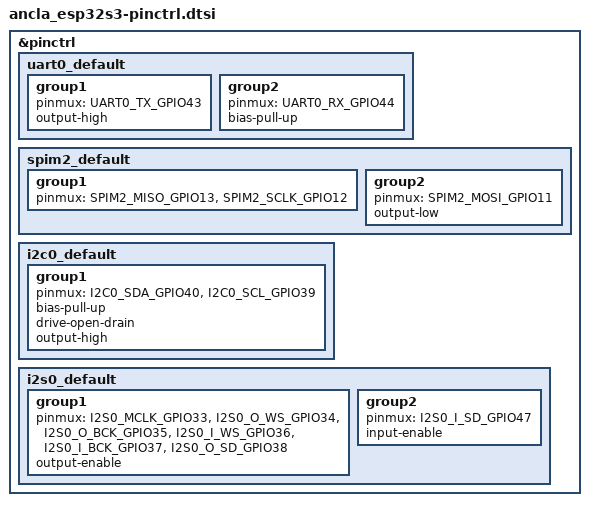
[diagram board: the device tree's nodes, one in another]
/*
 * Copyright (c) 2026 Innovaforce
 *
 * SPDX-License-Identifier: Apache-2.0
 */

#include <zephyr/dt-bindings/pinctrl/esp32s3-pinctrl.h>

&pinctrl {
	uart0_default: uart0_default {
		group1 {
			pinmux = <UART0_TX_GPIO43>;
			output-high;
		};

		group2 {
			pinmux = <UART0_RX_GPIO44>;
			bias-pull-up;
		};
	};

	spim2_default: spim2_default {
		group1 {
			/* No SPIM2_CSEL_GPIO10 here: CS is a plain GPIO (cs-gpios on &spi2)
			 * so the decadriver can hold it low to wake the DW3220. */
			pinmux = <SPIM2_MISO_GPIO13>,
				 <SPIM2_SCLK_GPIO12>;
		};

		group2 {
			pinmux = <SPIM2_MOSI_GPIO11>;
			output-low;
		};
	};

	i2c0_default: i2c0_default {
		group1 {
			pinmux = <I2C0_SDA_GPIO40>,
				 <I2C0_SCL_GPIO39>;
			bias-pull-up;
			drive-open-drain;
			output-high;
		};
	};

	i2s0_default: i2s0_default {
		group1 {
			/* Only O_SD (GPIO38) drives the LED; MCLK/O_WS/O_BCK/I_WS/I_BCK are spare, unconnected pins the I2S0 peripheral requires to be pinned anyway. */
			pinmux = <I2S0_MCLK_GPIO33>,
				 <I2S0_O_WS_GPIO34>,
				 <I2S0_O_BCK_GPIO35>,
				 <I2S0_I_WS_GPIO36>,
				 <I2S0_I_BCK_GPIO37>,
				 <I2S0_O_SD_GPIO38>;
			output-enable;
		};

		group2 {
			/* Unconnected; pinned only because the I2S0 peripheral requires it. */
			pinmux = <I2S0_I_SD_GPIO47>;
			input-enable;
		};
	};
};
